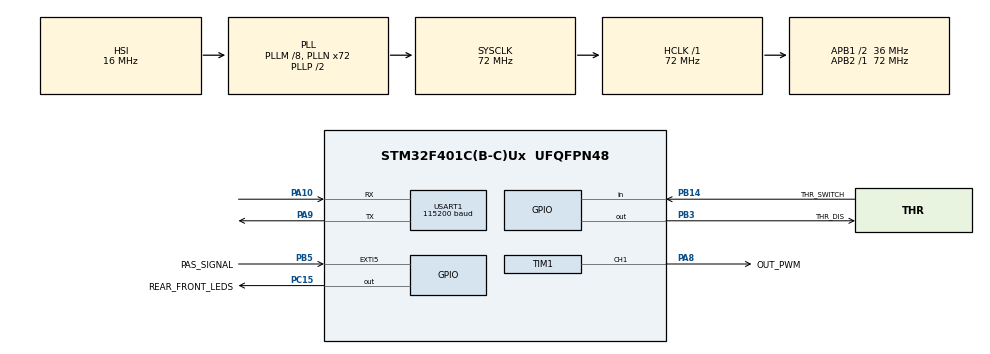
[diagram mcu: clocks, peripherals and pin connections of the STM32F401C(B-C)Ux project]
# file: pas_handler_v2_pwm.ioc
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Mcu.Family=STM32F4
Mcu.Name=STM32F401C(B-C)Ux
Mcu.Package=UFQFPN48
NVIC.EXTI9_5_IRQn=true\:0\:0\:false\:false\:true\:true\:true\:true
NVIC.PriorityGroup=NVIC_PRIORITYGROUP_4
PA10.Mode=Asynchronous
PA10.Signal=USART1_RX
PA8.GPIO_Label=OUT_PWM
PA8.GPIO_PuPd=GPIO_PULLDOWN
PA8.Signal=S_TIM1_CH1
PA9.Mode=Asynchronous
PA9.Signal=USART1_TX
PB14.GPIO_Label=THR_SWITCH
PB14.Signal=GPIO_Input
PB3.GPIO_Label=THR_DIS
PB3.Signal=GPIO_Output
PB5.GPIO_Label=PAS_SIGNAL
PB5.GPIO_ModeDefaultEXTI=GPIO_MODE_IT_RISING
PB5.GPIO_PuPd=GPIO_PULLDOWN
PB5.Signal=GPXTI5
PC15-OSC32_OUT.GPIO_Label=REAR_FRONT_LEDS
PC15-OSC32_OUT.GPIO_PuPd=GPIO_PULLDOWN
PC15-OSC32_OUT.GPIO_Speed=GPIO_SPEED_FREQ_LOW
PC15-OSC32_OUT.Signal=GPIO_Output
ProjectManager.HeapSize=0x200
ProjectManager.StackSize=0x400
ProjectManager.TargetToolchain=STM32CubeIDE
RCC.48MHZClocksFreq_Value=36000000
RCC.AHBFreq_Value=72000000
RCC.APB1CLKDivider=RCC_HCLK_DIV2
RCC.APB1Freq_Value=36000000
RCC.APB1TimFreq_Value=72000000
RCC.APB2Freq_Value=72000000
RCC.APB2TimFreq_Value=72000000
RCC.CortexFreq_Value=72000000
RCC.HCLKFreq_Value=72000000
RCC.HSE_VALUE=25000000
RCC.HSI_VALUE=16000000
RCC.LSE_VALUE=32768
RCC.PLLM=8
RCC.PLLN=72
RCC.SYSCLKFreq_VALUE=72000000
RCC.SYSCLKSource=RCC_SYSCLKSOURCE_PLLCLK
RCC.VCOOutputFreq_Value=144000000
SH.S_TIM1_CH1.0=TIM1_CH1,PWM Generation1 CH1
TIM1.Channel-PWM\ Generation1\ CH1=TIM_CHANNEL_1
TIM1.Period=1000-1
TIM1.Prescaler=72-1
USART1.BaudRate=115200
USART1.VirtualMode=VM_ASYNC
VP_TIM1_VS_ClockSourceINT.Mode=Internal
board=custom

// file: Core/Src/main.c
/* USER CODE BEGIN Header */
/**
 ******************************************************************************
 * @file           : main.c
 * @brief          : Main program body
 ******************************************************************************
 * @attention
 *
 * Copyright (c) 2024 STMicroelectronics.
 * All rights reserved.
 *
 * This software is licensed under terms that can be found in the LICENSE file
 * in the root directory of this software component.
 * If no LICENSE file comes with this software, it is provided AS-IS.
 *
 ******************************************************************************
 */
/* USER CODE END Header */
#include "main.h"

/* USER CODE BEGIN Includes */
#include <stdio.h>
#include <string.h>

#include "helpers.h"
#include "algorithm.h"
/* USER CODE END Includes */

/* USER CODE BEGIN PD */
//#define LOG_VERBOSE
/* USER CODE END PD */

TIM_HandleTypeDef htim1;

UART_HandleTypeDef huart1;

void SystemClock_Config(void);
static void MX_GPIO_Init(void);
static void MX_USART1_UART_Init(void);
static void MX_TIM1_Init(void);

/* USER CODE BEGIN 0 */

/* Global variables ----------------------------------------------------------*/
TIM_HandleTypeDef htim1;
UART_HandleTypeDef huart1;

void HAL_GPIO_EXTI_Callback(uint16_t GPIO_Pin) {
	if (GPIO_Pin == GPIO_PIN_5)
		pasCounter++;

}

/* USER CODE END 0 */

int main(void)
{

  /* MCU Configuration--------------------------------------------------------*/

  /* Reset of all peripherals, Initializes the Flash interface and the Systick. */
  HAL_Init();

  /* Configure the system clock */
  SystemClock_Config();

  /* Initialize all configured peripherals */
  MX_GPIO_Init();
  MX_USART1_UART_Init();
  MX_TIM1_Init();
  /* USER CODE BEGIN 2 */
	init();

  /* USER CODE END 2 */

  /* Infinite loop */
  /* USER CODE BEGIN WHILE */
	while (1) {
		float timeS = ((float) HAL_GetTick() - (float) lastPasResetTick) / 1000.0;

		if (!runAlgorithm(timeS))
			continue;

    /* USER CODE END WHILE */

	}
}

void SystemClock_Config(void)
{
  RCC_OscInitTypeDef RCC_OscInitStruct = {0};
  RCC_ClkInitTypeDef RCC_ClkInitStruct = {0};

  /** Configure the main internal regulator output voltage
  */
  __HAL_RCC_PWR_CLK_ENABLE();
  __HAL_PWR_VOLTAGESCALING_CONFIG(PWR_REGULATOR_VOLTAGE_SCALE2);

  /** Initializes the RCC Oscillators according to the specified parameters
  * in the RCC_OscInitTypeDef structure.
  */
  RCC_OscInitStruct.OscillatorType = RCC_OSCILLATORTYPE_HSI;
  RCC_OscInitStruct.HSIState = RCC_HSI_ON;
  RCC_OscInitStruct.HSICalibrationValue = RCC_HSICALIBRATION_DEFAULT;
  RCC_OscInitStruct.PLL.PLLState = RCC_PLL_ON;
  RCC_OscInitStruct.PLL.PLLSource = RCC_PLLSOURCE_HSI;
  RCC_OscInitStruct.PLL.PLLM = 8;
  RCC_OscInitStruct.PLL.PLLN = 72;
  RCC_OscInitStruct.PLL.PLLP = RCC_PLLP_DIV2;
  RCC_OscInitStruct.PLL.PLLQ = 4;
  if (HAL_RCC_OscConfig(&RCC_OscInitStruct) != HAL_OK)
  {
    Error_Handler();
  }

  /** Initializes the CPU, AHB and APB buses clocks
  */
  RCC_ClkInitStruct.ClockType = RCC_CLOCKTYPE_HCLK|RCC_CLOCKTYPE_SYSCLK
                              |RCC_CLOCKTYPE_PCLK1|RCC_CLOCKTYPE_PCLK2;
  RCC_ClkInitStruct.SYSCLKSource = RCC_SYSCLKSOURCE_PLLCLK;
  RCC_ClkInitStruct.AHBCLKDivider = RCC_SYSCLK_DIV1;
  RCC_ClkInitStruct.APB1CLKDivider = RCC_HCLK_DIV2;
  RCC_ClkInitStruct.APB2CLKDivider = RCC_HCLK_DIV1;

  if (HAL_RCC_ClockConfig(&RCC_ClkInitStruct, FLASH_LATENCY_2) != HAL_OK)
  {
    Error_Handler();
  }
}

static void MX_TIM1_Init(void)
{

  TIM_ClockConfigTypeDef sClockSourceConfig = {0};
  TIM_MasterConfigTypeDef sMasterConfig = {0};
  TIM_OC_InitTypeDef sConfigOC = {0};
  TIM_BreakDeadTimeConfigTypeDef sBreakDeadTimeConfig = {0};

  htim1.Instance = TIM1;
  htim1.Init.Prescaler = 72-1;
  htim1.Init.CounterMode = TIM_COUNTERMODE_UP;
  htim1.Init.Period = 1000-1;
  htim1.Init.ClockDivision = TIM_CLOCKDIVISION_DIV1;
  htim1.Init.RepetitionCounter = 0;
  htim1.Init.AutoReloadPreload = TIM_AUTORELOAD_PRELOAD_DISABLE;
  if (HAL_TIM_Base_Init(&htim1) != HAL_OK)
  {
    Error_Handler();
  }
  sClockSourceConfig.ClockSource = TIM_CLOCKSOURCE_INTERNAL;
  if (HAL_TIM_ConfigClockSource(&htim1, &sClockSourceConfig) != HAL_OK)
  {
    Error_Handler();
  }
  if (HAL_TIM_PWM_Init(&htim1) != HAL_OK)
  {
    Error_Handler();
  }
  sMasterConfig.MasterOutputTrigger = TIM_TRGO_RESET;
  sMasterConfig.MasterSlaveMode = TIM_MASTERSLAVEMODE_DISABLE;
  if (HAL_TIMEx_MasterConfigSynchronization(&htim1, &sMasterConfig) != HAL_OK)
  {
    Error_Handler();
  }
  sConfigOC.OCMode = TIM_OCMODE_PWM1;
  sConfigOC.Pulse = 0;
  sConfigOC.OCPolarity = TIM_OCPOLARITY_HIGH;
  sConfigOC.OCNPolarity = TIM_OCNPOLARITY_HIGH;
  sConfigOC.OCFastMode = TIM_OCFAST_DISABLE;
  sConfigOC.OCIdleState = TIM_OCIDLESTATE_RESET;
  sConfigOC.OCNIdleState = TIM_OCNIDLESTATE_RESET;
  if (HAL_TIM_PWM_ConfigChannel(&htim1, &sConfigOC, TIM_CHANNEL_1) != HAL_OK)
  {
    Error_Handler();
  }
  sBreakDeadTimeConfig.OffStateRunMode = TIM_OSSR_DISABLE;
  sBreakDeadTimeConfig.OffStateIDLEMode = TIM_OSSI_DISABLE;
  sBreakDeadTimeConfig.LockLevel = TIM_LOCKLEVEL_OFF;
  sBreakDeadTimeConfig.DeadTime = 0;
  sBreakDeadTimeConfig.BreakState = TIM_BREAK_DISABLE;
  sBreakDeadTimeConfig.BreakPolarity = TIM_BREAKPOLARITY_HIGH;
  sBreakDeadTimeConfig.AutomaticOutput = TIM_AUTOMATICOUTPUT_DISABLE;
  if (HAL_TIMEx_ConfigBreakDeadTime(&htim1, &sBreakDeadTimeConfig) != HAL_OK)
  {
    Error_Handler();
  }
  HAL_TIM_MspPostInit(&htim1);

}

static void MX_USART1_UART_Init(void)
{

  huart1.Instance = USART1;
  huart1.Init.BaudRate = 115200;
  huart1.Init.WordLength = UART_WORDLENGTH_8B;
  huart1.Init.StopBits = UART_STOPBITS_1;
  huart1.Init.Parity = UART_PARITY_NONE;
  huart1.Init.Mode = UART_MODE_TX_RX;
  huart1.Init.HwFlowCtl = UART_HWCONTROL_NONE;
  huart1.Init.OverSampling = UART_OVERSAMPLING_16;
  if (HAL_UART_Init(&huart1) != HAL_OK)
  {
    Error_Handler();
  }

}

static void MX_GPIO_Init(void)
{
  GPIO_InitTypeDef GPIO_InitStruct = {0};

  /* GPIO Ports Clock Enable */
  __HAL_RCC_GPIOC_CLK_ENABLE();
  __HAL_RCC_GPIOB_CLK_ENABLE();
  __HAL_RCC_GPIOA_CLK_ENABLE();

  /*Configure GPIO pin Output Level */
  HAL_GPIO_WritePin(REAR_FRONT_LEDS_GPIO_Port, REAR_FRONT_LEDS_Pin, GPIO_PIN_RESET);

  /*Configure GPIO pin Output Level */
  HAL_GPIO_WritePin(THR_DIS_GPIO_Port, THR_DIS_Pin, GPIO_PIN_RESET);

  /*Configure GPIO pin : REAR_FRONT_LEDS_Pin */
  GPIO_InitStruct.Pin = REAR_FRONT_LEDS_Pin;
  GPIO_InitStruct.Mode = GPIO_MODE_OUTPUT_PP;
  GPIO_InitStruct.Pull = GPIO_PULLDOWN;
  GPIO_InitStruct.Speed = GPIO_SPEED_FREQ_LOW;
  HAL_GPIO_Init(REAR_FRONT_LEDS_GPIO_Port, &GPIO_InitStruct);

  /*Configure GPIO pin : THR_SWITCH_Pin */
  GPIO_InitStruct.Pin = THR_SWITCH_Pin;
  GPIO_InitStruct.Mode = GPIO_MODE_INPUT;
  GPIO_InitStruct.Pull = GPIO_NOPULL;
  HAL_GPIO_Init(THR_SWITCH_GPIO_Port, &GPIO_InitStruct);

  /*Configure GPIO pin : THR_DIS_Pin */
  GPIO_InitStruct.Pin = THR_DIS_Pin;
  GPIO_InitStruct.Mode = GPIO_MODE_OUTPUT_PP;
  GPIO_InitStruct.Pull = GPIO_NOPULL;
  GPIO_InitStruct.Speed = GPIO_SPEED_FREQ_LOW;
  HAL_GPIO_Init(THR_DIS_GPIO_Port, &GPIO_InitStruct);

  /*Configure GPIO pin : PAS_SIGNAL_Pin */
  GPIO_InitStruct.Pin = PAS_SIGNAL_Pin;
  GPIO_InitStruct.Mode = GPIO_MODE_IT_RISING;
  GPIO_InitStruct.Pull = GPIO_PULLDOWN;
  HAL_GPIO_Init(PAS_SIGNAL_GPIO_Port, &GPIO_InitStruct);

  /* EXTI interrupt init*/
  HAL_NVIC_SetPriority(EXTI9_5_IRQn, 0, 0);
  HAL_NVIC_EnableIRQ(EXTI9_5_IRQn);

}

void Error_Handler(void)
{
	__disable_irq();
	while (1) {
	}
}
